VERSION ""

NS_ :

BS_:

BU_: Powertrain_Brake_ECU TCS_Master_Node Wheel_Speed_Module Driver_Input_ECU

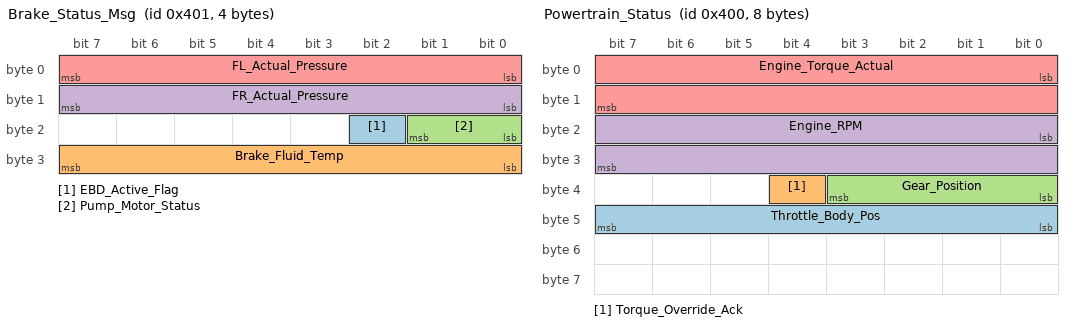
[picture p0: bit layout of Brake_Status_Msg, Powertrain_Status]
BO_ 1025 Brake_Status_Msg: 4 Powertrain_Brake_ECU
 SG_ EBD_Active_Flag : 18|1@1+ (1,0) [0|1] "Flag" Vector__XXX
 SG_ Brake_Fluid_Temp : 24|8@1+ (1,-40) [-40|200] "C" Vector__XXX
 SG_ Pump_Motor_Status : 16|2@1+ (1,0) [0|3] "Enum" Vector__XXX
 SG_ FR_Actual_Pressure : 8|8@1+ (1,0) [0|200] "bar" Vector__XXX
 SG_ FL_Actual_Pressure : 0|8@1+ (1,0) [0|200] "bar"  TCS_Master_Node

BO_ 1024 Powertrain_Status: 8 Powertrain_Brake_ECU
 SG_ Throttle_Body_Pos : 40|8@1+ (1,0) [0|100] "%" Vector__XXX
 SG_ Torque_Override_Ack : 36|1@1+ (1,0) [0|1] "Flag" Vector__XXX
 SG_ Gear_Position : 32|4@1+ (1,0) [0|15] "Enum" Vector__XXX
 SG_ Engine_RPM : 16|16@1+ (1,0) [0|8000] "RPM" Vector__XXX
 SG_ Engine_Torque_Actual : 0|16@1+ (0.5,0) [0|500] "Nm"  TCS_Master_Node

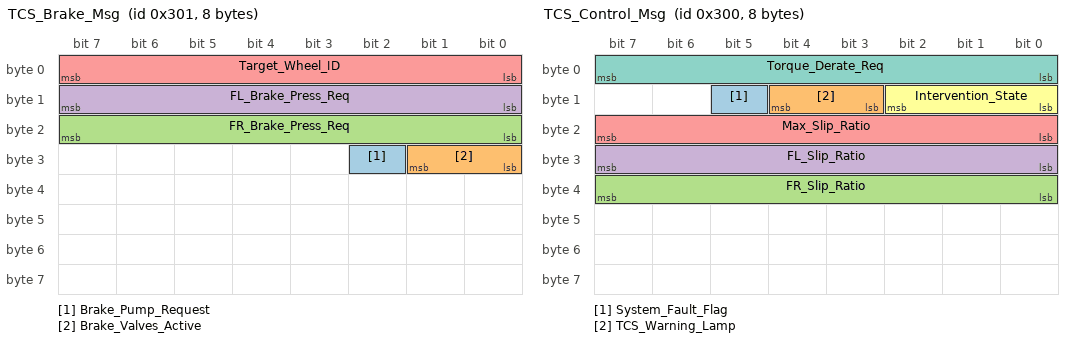
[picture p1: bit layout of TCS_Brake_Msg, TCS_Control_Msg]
BO_ 769 TCS_Brake_Msg: 8 TCS_Master_Node
 SG_ Brake_Pump_Request : 26|1@1+ (1,0) [0|1] "Flag" Vector__XXX
 SG_ Brake_Valves_Active : 24|2@1+ (1,0) [0|3] "Flag"  TCS_Master_Node
 SG_ FR_Brake_Press_Req : 16|8@1+ (1,0) [0|200] "bar" Vector__XXX
 SG_ FL_Brake_Press_Req : 8|8@1+ (1,0) [0|200] "bar" Vector__XXX
 SG_ Target_Wheel_ID : 0|8@1+ (1,0) [0|4] "Enum" Vector__XXX

BO_ 768 TCS_Control_Msg: 8 TCS_Master_Node
 SG_ System_Fault_Flag : 13|1@1+ (1,0) [0|1] "Flag" Vector__XXX
 SG_ TCS_Warning_Lamp : 11|2@1+ (1,0) [0|3] "Enum" Vector__XXX
 SG_ FR_Slip_Ratio : 32|8@1+ (0.5,0) [0|100] "%" Vector__XXX
 SG_ FL_Slip_Ratio : 24|8@1+ (0.5,0) [0|100] "%" Vector__XXX
 SG_ Max_Slip_Ratio : 16|8@1+ (0.5,0) [0|100] "%" Vector__XXX
 SG_ Intervention_State : 8|3@1+ (1,0) [0|7] "Enum" Vector__XXX
 SG_ Torque_Derate_Req : 0|8@1+ (1,0) [0|100] "%"  TCS_Master_Node

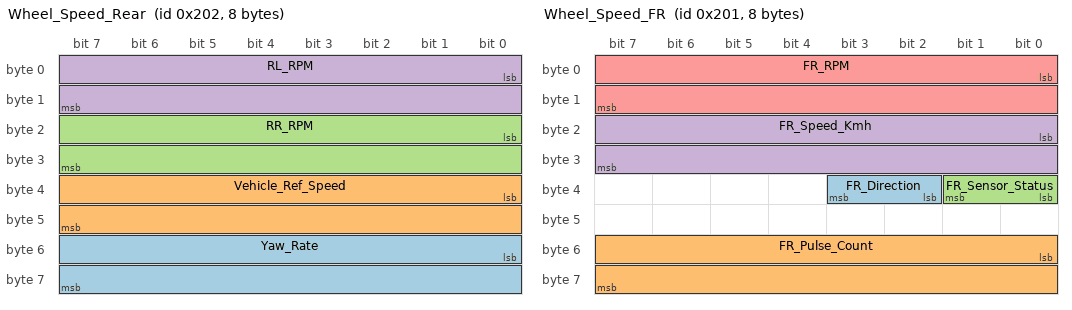
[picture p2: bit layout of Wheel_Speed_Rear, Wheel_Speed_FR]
BO_ 514 Wheel_Speed_Rear: 8 Wheel_Speed_Module
 SG_ Yaw_Rate : 48|16@1+ (0.1,-100) [-100|100] "deg/s" Vector__XXX
 SG_ Vehicle_Ref_Speed : 32|16@1+ (0.1,0) [0|250] "km/h" Vector__XXX
 SG_ RR_RPM : 16|16@1+ (1,0) [0|3000] "RPM" Vector__XXX
 SG_ RL_RPM : 0|16@1+ (1,0) [0|3000] "RPM"  TCS_Master_Node

BO_ 513 Wheel_Speed_FR: 8 Wheel_Speed_Module
 SG_ FR_Direction : 34|2@1+ (1,0) [0|3] "Enum" Vector__XXX
 SG_ FR_Pulse_Count : 48|16@1+ (1,0) [0|65535] "counts" Vector__XXX
 SG_ FR_Sensor_Status : 32|2@1+ (1,0) [0|3] "Enum" Vector__XXX
 SG_ FR_Speed_Kmh : 16|16@1+ (0.1,0) [0|250] "km/h" Vector__XXX
 SG_ FR_RPM : 0|16@1+ (1,0) [0|3000] "RPM"  TCS_Master_Node

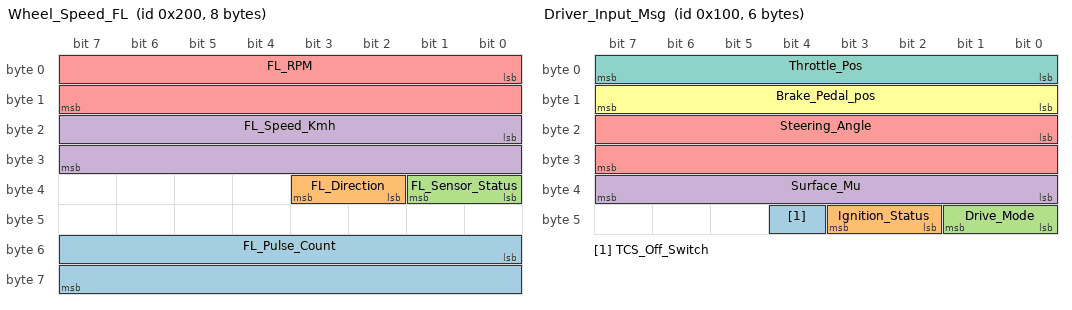
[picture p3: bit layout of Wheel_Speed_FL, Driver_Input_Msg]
BO_ 512 Wheel_Speed_FL: 8 Wheel_Speed_Module
 SG_ FL_Pulse_Count : 48|16@1+ (1,0) [0|65535] "counts" Vector__XXX
 SG_ FL_Direction : 34|2@1+ (1,0) [0|3] "Enum" Vector__XXX
 SG_ FL_Sensor_Status : 32|2@1+ (1,0) [0|3] "Enum" Vector__XXX
 SG_ FL_Speed_Kmh : 16|16@1+ (0.1,0) [0|250] "km/h" Vector__XXX
 SG_ FL_RPM : 0|16@1+ (1,0) [0|3000] "RPM"  TCS_Master_Node

BO_ 256 Driver_Input_Msg: 6 Driver_Input_ECU
 SG_ TCS_Off_Switch : 44|1@1+ (1,0) [0|1] "Flag" Vector__XXX
 SG_ Ignition_Status : 42|2@1+ (1,0) [-0|3] "Enum" Vector__XXX
 SG_ Drive_Mode : 40|2@1+ (1,0) [0|3] "Enum" Vector__XXX
 SG_ Surface_Mu : 32|8@1+ (0.01,0) [0.2|0.8] "" Vector__XXX
 SG_ Steering_Angle : 16|16@1+ (1,-500) [-500|500] "deg" Vector__XXX
 SG_ Brake_Pedal_pos : 8|8@1+ (1,0) [0|100] "%" Vector__XXX
 SG_ Throttle_Pos : 0|8@1+ (1,0) [0|100] "%"  TCS_Master_Node

BA_DEF_  "BusType" STRING ;
BA_DEF_DEF_  "BusType" "CAN";
